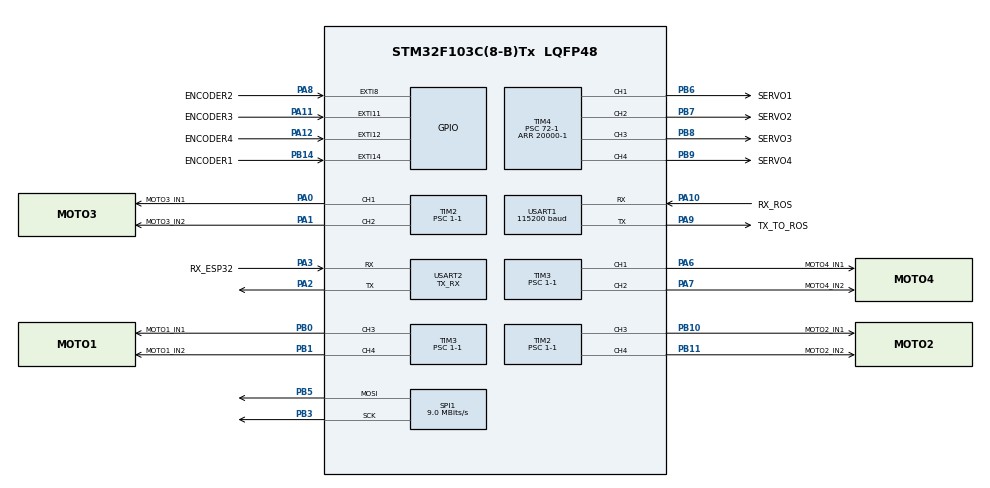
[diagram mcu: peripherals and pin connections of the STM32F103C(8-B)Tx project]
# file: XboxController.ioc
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Dma.Request0=USART2_RX
Dma.Request1=SPI1_TX
Dma.Request2=USART1_RX
Dma.Request3=USART1_TX
Dma.SPI1_TX.1.Direction=DMA_MEMORY_TO_PERIPH
Dma.SPI1_TX.1.Instance=DMA1_Channel3
Dma.SPI1_TX.1.MemDataAlignment=DMA_MDATAALIGN_BYTE
Dma.SPI1_TX.1.MemInc=DMA_MINC_ENABLE
Dma.SPI1_TX.1.Mode=DMA_NORMAL
Dma.SPI1_TX.1.PeriphDataAlignment=DMA_PDATAALIGN_BYTE
Dma.SPI1_TX.1.PeriphInc=DMA_PINC_DISABLE
Dma.SPI1_TX.1.Priority=DMA_PRIORITY_MEDIUM
Dma.USART1_RX.2.Direction=DMA_PERIPH_TO_MEMORY
Dma.USART1_RX.2.Instance=DMA1_Channel5
Dma.USART1_RX.2.MemDataAlignment=DMA_MDATAALIGN_BYTE
Dma.USART1_RX.2.MemInc=DMA_MINC_ENABLE
Dma.USART1_RX.2.Mode=DMA_NORMAL
Dma.USART1_RX.2.PeriphDataAlignment=DMA_PDATAALIGN_BYTE
Dma.USART1_RX.2.PeriphInc=DMA_PINC_DISABLE
Dma.USART1_RX.2.Priority=DMA_PRIORITY_LOW
Dma.USART1_TX.3.Direction=DMA_MEMORY_TO_PERIPH
Dma.USART1_TX.3.Instance=DMA1_Channel4
Dma.USART1_TX.3.MemDataAlignment=DMA_MDATAALIGN_BYTE
Dma.USART1_TX.3.MemInc=DMA_MINC_ENABLE
Dma.USART1_TX.3.Mode=DMA_NORMAL
Dma.USART1_TX.3.PeriphDataAlignment=DMA_PDATAALIGN_BYTE
Dma.USART1_TX.3.PeriphInc=DMA_PINC_DISABLE
Dma.USART1_TX.3.Priority=DMA_PRIORITY_LOW
Dma.USART2_RX.0.Direction=DMA_PERIPH_TO_MEMORY
Dma.USART2_RX.0.Instance=DMA1_Channel6
Dma.USART2_RX.0.MemDataAlignment=DMA_MDATAALIGN_BYTE
Dma.USART2_RX.0.MemInc=DMA_MINC_ENABLE
Dma.USART2_RX.0.Mode=DMA_NORMAL
Dma.USART2_RX.0.PeriphDataAlignment=DMA_PDATAALIGN_BYTE
Dma.USART2_RX.0.PeriphInc=DMA_PINC_DISABLE
Dma.USART2_RX.0.Priority=DMA_PRIORITY_HIGH
Mcu.Family=STM32F1
Mcu.Name=STM32F103C(8-B)Tx
Mcu.Package=LQFP48
NVIC.DMA1_Channel3_IRQn=true\:0\:0\:false\:false\:true\:false\:true\:true
NVIC.DMA1_Channel4_IRQn=true\:5\:0\:true\:false\:true\:true\:true\:true
NVIC.DMA1_Channel5_IRQn=true\:5\:0\:true\:false\:true\:true\:true\:true
NVIC.DMA1_Channel6_IRQn=true\:5\:0\:true\:false\:true\:true\:true\:true
NVIC.EXTI15_10_IRQn=true\:7\:0\:true\:false\:true\:true\:true\:true
NVIC.EXTI9_5_IRQn=true\:7\:0\:true\:false\:true\:true\:true\:true
NVIC.PriorityGroup=NVIC_PRIORITYGROUP_4
NVIC.SPI1_IRQn=true\:0\:0\:false\:false\:true\:true\:true\:true
NVIC.TIM1_UP_IRQn=true\:4\:0\:true\:false\:true\:true\:true\:true
NVIC.USART1_IRQn=true\:5\:0\:true\:false\:false\:true\:true\:true
NVIC.USART2_IRQn=true\:5\:0\:true\:false\:false\:true\:true\:true
PA0-WKUP.GPIO_Label=MOTO3_IN1
PA0-WKUP.Signal=S_TIM2_CH1_ETR
PA1.GPIO_Label=MOTO3_IN2
PA1.Signal=S_TIM2_CH2
PA10.GPIO_Label=RX_ROS
PA10.Mode=Asynchronous
PA10.Signal=USART1_RX
PA11.GPIO_Label=ENCODER3
PA11.GPIO_ModeDefaultEXTI=GPIO_MODE_IT_RISING_FALLING
PA11.GPIO_PuPd=GPIO_PULLUP
PA11.Signal=GPXTI11
PA12.GPIO_Label=ENCODER4
PA12.GPIO_ModeDefaultEXTI=GPIO_MODE_IT_RISING_FALLING
PA12.GPIO_PuPd=GPIO_PULLUP
PA12.Signal=GPXTI12
PA13.Mode=Serial_Wire
PA13.Signal=SYS_JTMS-SWDIO
PA14.Mode=Serial_Wire
PA14.Signal=SYS_JTCK-SWCLK
PA2.Mode=Asynchronous
PA2.Signal=USART2_TX
PA3.GPIO_Label=RX_ESP32
PA3.Mode=Asynchronous
PA3.Signal=USART2_RX
PA6.GPIO_Label=MOTO4_IN1
PA6.Signal=S_TIM3_CH1
PA7.GPIO_Label=MOTO4_IN2
PA7.Signal=S_TIM3_CH2
PA8.GPIO_Label=ENCODER2
PA8.GPIO_ModeDefaultEXTI=GPIO_MODE_IT_RISING_FALLING
PA8.GPIO_PuPd=GPIO_PULLUP
PA8.Signal=GPXTI8
PA9.GPIO_Label=TX_TO_ROS
PA9.Mode=Asynchronous
PA9.Signal=USART1_TX
PB0.GPIO_Label=MOTO1_IN1
PB0.Signal=S_TIM3_CH3
PB1.GPIO_Label=MOTO1_IN2
PB1.Signal=S_TIM3_CH4
PB10.GPIO_Label=MOTO2_IN1
PB10.Signal=S_TIM2_CH3
PB11.GPIO_Label=MOTO2_IN2
PB11.Signal=S_TIM2_CH4
PB14.GPIO_Label=ENCODER1
PB14.GPIO_ModeDefaultEXTI=GPIO_MODE_IT_RISING_FALLING
PB14.GPIO_PuPd=GPIO_PULLUP
PB14.Signal=GPXTI14
PB3.Mode=TX_Only_Simplex_Unidirect_Master
PB3.Signal=SPI1_SCK
PB5.Mode=TX_Only_Simplex_Unidirect_Master
PB5.Signal=SPI1_MOSI
PB6.GPIO_Label=SERVO1
PB6.Signal=S_TIM4_CH1
PB7.GPIO_Label=SERVO2
PB7.Signal=S_TIM4_CH2
PB8.GPIO_Label=SERVO3
PB8.Signal=S_TIM4_CH3
PB9.GPIO_Label=SERVO4
PB9.Signal=S_TIM4_CH4
PD0-OSC_IN.Mode=HSE-External-Oscillator
PD0-OSC_IN.Signal=RCC_OSC_IN
PD1-OSC_OUT.Mode=HSE-External-Oscillator
PD1-OSC_OUT.Signal=RCC_OSC_OUT
ProjectManager.HeapSize=0x200
ProjectManager.StackSize=0x400
ProjectManager.TargetToolchain=MDK-ARM V5
RCC.AHBFreq_Value=72000000
RCC.APB1CLKDivider=RCC_HCLK_DIV2
RCC.APB1Freq_Value=36000000
RCC.APB1TimFreq_Value=72000000
RCC.APB2Freq_Value=72000000
RCC.APB2TimFreq_Value=72000000
RCC.HCLKFreq_Value=72000000
RCC.PLLMUL=RCC_PLL_MUL9
RCC.PLLSourceVirtual=RCC_PLLSOURCE_HSE
RCC.SYSCLKFreq_VALUE=72000000
RCC.SYSCLKSource=RCC_SYSCLKSOURCE_PLLCLK
RCC.USBFreq_Value=72000000
SH.S_TIM2_CH1_ETR.0=TIM2_CH1,PWM Generation1 CH1
SH.S_TIM2_CH2.0=TIM2_CH2,PWM Generation2 CH2
SH.S_TIM2_CH3.0=TIM2_CH3,PWM Generation3 CH3
SH.S_TIM2_CH4.0=TIM2_CH4,PWM Generation4 CH4
SH.S_TIM3_CH1.0=TIM3_CH1,PWM Generation1 CH1
SH.S_TIM3_CH2.0=TIM3_CH2,PWM Generation2 CH2
SH.S_TIM3_CH3.0=TIM3_CH3,PWM Generation3 CH3
SH.S_TIM3_CH4.0=TIM3_CH4,PWM Generation4 CH4
SH.S_TIM4_CH1.0=TIM4_CH1,PWM Generation1 CH1
SH.S_TIM4_CH2.0=TIM4_CH2,PWM Generation2 CH2
SH.S_TIM4_CH3.0=TIM4_CH3,PWM Generation3 CH3
SH.S_TIM4_CH4.0=TIM4_CH4,PWM Generation4 CH4
SPI1.BaudRatePrescaler=SPI_BAUDRATEPRESCALER_8
SPI1.CLKPhase=SPI_PHASE_2EDGE
SPI1.CLKPolarity=SPI_POLARITY_HIGH
SPI1.CalculateBaudRate=9.0 MBits/s
SPI1.Direction=SPI_DIRECTION_2LINES
SPI1.Mode=SPI_MODE_MASTER
SPI1.VirtualType=VM_MASTER
TIM1.AutoReloadPreload=TIM_AUTORELOAD_PRELOAD_ENABLE
TIM1.Period=1000-1
TIM1.Prescaler=720-1
TIM2.AutoReloadPreload=TIM_AUTORELOAD_PRELOAD_DISABLE
TIM2.Channel-PWM\ Generation1\ CH1=TIM_CHANNEL_1
TIM2.Channel-PWM\ Generation2\ CH2=TIM_CHANNEL_2
TIM2.Channel-PWM\ Generation3\ CH3=TIM_CHANNEL_3
TIM2.Channel-PWM\ Generation4\ CH4=TIM_CHANNEL_4
TIM2.Period=3600-1
TIM2.Prescaler=1-1
TIM3.AutoReloadPreload=TIM_AUTORELOAD_PRELOAD_DISABLE
TIM3.Channel-PWM\ Generation1\ CH1=TIM_CHANNEL_1
TIM3.Channel-PWM\ Generation2\ CH2=TIM_CHANNEL_2
TIM3.Channel-PWM\ Generation3\ CH3=TIM_CHANNEL_3
TIM3.Channel-PWM\ Generation4\ CH4=TIM_CHANNEL_4
TIM3.Period=3600-1
TIM3.Prescaler=1-1
TIM4.AutoReloadPreload=TIM_AUTORELOAD_PRELOAD_ENABLE
TIM4.Channel-PWM\ Generation1\ CH1=TIM_CHANNEL_1
TIM4.Channel-PWM\ Generation2\ CH2=TIM_CHANNEL_2
TIM4.Channel-PWM\ Generation3\ CH3=TIM_CHANNEL_3
TIM4.Channel-PWM\ Generation4\ CH4=TIM_CHANNEL_4
TIM4.Period=20000-1
TIM4.Prescaler=72-1
USART1.BaudRate=115200
USART1.VirtualMode=VM_ASYNC
USART2.Mode=MODE_TX_RX
USART2.VirtualMode=VM_ASYNC
VP_TIM1_VS_ClockSourceINT.Mode=Internal
VP_TIM2_VS_ClockSourceINT.Mode=Internal
VP_TIM3_VS_ClockSourceINT.Mode=Internal
VP_TIM4_VS_ClockSourceINT.Mode=Internal
board=custom

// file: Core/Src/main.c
/* USER CODE BEGIN Header */
/**
 ******************************************************************************
 * @file           : main.c
 * @brief          : Main program body
 ******************************************************************************
 * @attention
 *
 * Copyright (c) 2023 STMicroelectronics.
 * All rights reserved.
 *
 * This software is licensed under terms that can be found in the LICENSE file
 * in the root directory of this software component.
 * If no LICENSE file comes with this software, it is provided AS-IS.
 *
 ******************************************************************************
 */
/* USER CODE END Header */
#include "main.h"
#include "dma.h"
#include "spi.h"
#include "tim.h"
#include "usart.h"
#include "gpio.h"

/* USER CODE BEGIN Includes */
#include "init.h"

/* USER CODE END Includes */

void SystemClock_Config(void);

int main(void)
{

  /* MCU Configuration--------------------------------------------------------*/

  /* Reset of all peripherals, Initializes the Flash interface and the Systick. */
  HAL_Init();

  /* Configure the system clock */
  SystemClock_Config();

  /* Initialize all configured peripherals */
  MX_GPIO_Init();
  MX_DMA_Init();
  MX_TIM1_Init();
  MX_TIM3_Init();
  MX_TIM4_Init();
  MX_SPI1_Init();
  MX_TIM2_Init();
  MX_USART2_UART_Init();
  MX_USART1_UART_Init();
  /* USER CODE BEGIN 2 */

  Init_all_func();

  /* USER CODE END 2 */

  /* Infinite loop */
  /* USER CODE BEGIN WHILE */
  while (1)
  {

    // HAL_Delay(10);
    /* USER CODE END WHILE */

  }
}

void SystemClock_Config(void)
{
  LL_FLASH_SetLatency(LL_FLASH_LATENCY_2);
  while(LL_FLASH_GetLatency()!= LL_FLASH_LATENCY_2)
  {
  }
  LL_RCC_HSE_Enable();

   /* Wait till HSE is ready */
  while(LL_RCC_HSE_IsReady() != 1)
  {

  }
  LL_RCC_PLL_ConfigDomain_SYS(LL_RCC_PLLSOURCE_HSE_DIV_1, LL_RCC_PLL_MUL_9);
  LL_RCC_PLL_Enable();

   /* Wait till PLL is ready */
  while(LL_RCC_PLL_IsReady() != 1)
  {

  }
  LL_RCC_SetAHBPrescaler(LL_RCC_SYSCLK_DIV_1);
  LL_RCC_SetAPB1Prescaler(LL_RCC_APB1_DIV_2);
  LL_RCC_SetAPB2Prescaler(LL_RCC_APB2_DIV_1);
  LL_RCC_SetSysClkSource(LL_RCC_SYS_CLKSOURCE_PLL);

   /* Wait till System clock is ready */
  while(LL_RCC_GetSysClkSource() != LL_RCC_SYS_CLKSOURCE_STATUS_PLL)
  {

  }
  LL_SetSystemCoreClock(72000000);

   /* Update the time base */
  if (HAL_InitTick (TICK_INT_PRIORITY) != HAL_OK)
  {
    Error_Handler();
  }
}

void Error_Handler(void)
{
  __disable_irq();
  while (1)
  {
  }
}
